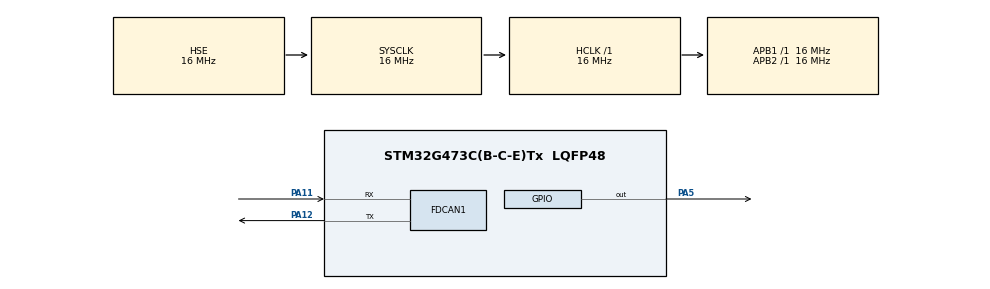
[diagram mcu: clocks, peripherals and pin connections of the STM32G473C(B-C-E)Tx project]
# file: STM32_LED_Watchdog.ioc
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FDCAN1.AutoRetransmission=ENABLE
FDCAN1.CalculateBaudRateNominal=1000000
FDCAN1.CalculateTimeBitNominal=1000
FDCAN1.CalculateTimeQuantumNominal=62.5
FDCAN1.NominalPrescaler=1
FDCAN1.NominalTimeSeg1=13
FDCAN1.NominalTimeSeg2=2
FDCAN1.StdFiltersNbr=1
IWDG.Prescaler=IWDG_PRESCALER_32
Mcu.Family=STM32G4
Mcu.Name=STM32G473C(B-C-E)Tx
Mcu.Package=LQFP48
NVIC.PriorityGroup=NVIC_PRIORITYGROUP_4
NVIC.TIM6_DAC_IRQn=true\:0\:0\:false\:false\:true\:true\:true\:true
PA11.Mode=FDCAN_Activate
PA11.Signal=FDCAN1_RX
PA12.Mode=FDCAN_Activate
PA12.Signal=FDCAN1_TX
PA5.Signal=GPIO_Output
PF0-OSC_IN.Mode=HSE-External-Clock-Source
PF0-OSC_IN.Signal=RCC_OSC_IN
ProjectManager.HeapSize=0x200
ProjectManager.StackSize=0x400
ProjectManager.TargetToolchain=STM32CubeIDE
RCC.AHBFreq_Value=16000000
RCC.APB1Freq_Value=16000000
RCC.APB1TimFreq_Value=16000000
RCC.APB2Freq_Value=16000000
RCC.APB2TimFreq_Value=16000000
RCC.CortexFreq_Value=16000000
RCC.EXTERNAL_CLOCK_VALUE=12288000
RCC.HCLKFreq_Value=16000000
RCC.HSE_VALUE=16000000
RCC.HSI48_VALUE=48000000
RCC.HSI_VALUE=16000000
RCC.LSE_VALUE=32768
RCC.PLLSourceVirtual=RCC_PLLSOURCE_HSE
RCC.SYSCLKFreq_VALUE=16000000
RCC.SYSCLKSource=RCC_SYSCLKSOURCE_HSE
RCC.USBFreq_Value=64000000
RCC.VCOOutputFreq_Value=128000000
TIM6.PeriodNoDither=99
TIM6.Prescaler=15999
VP_IWDG_VS_IWDG.Mode=IWDG_Activate
VP_SYS_VS_DBSignals.Mode=DisableDeadBatterySignals
VP_TIM6_VS_ClockSourceINT.Mode=Enable_Timer
board=custom

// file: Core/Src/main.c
/* USER CODE BEGIN Header */
/**
  ******************************************************************************
  * @file           : main.c
  * @brief          : Main program body
  ******************************************************************************
  * @attention
  *
  * Copyright (c) 2026 STMicroelectronics.
  * All rights reserved.
  *
  * This software is licensed under terms that can be found in the LICENSE file
  * in the root directory of this software component.
  * If no LICENSE file comes with this software, it is provided AS-IS.
  *
  ******************************************************************************
  */
/* USER CODE END Header */
#include "main.h"
#include "fdcan.h"
#include "iwdg.h"
#include "tim.h"
#include "gpio.h"

/* USER CODE BEGIN PV */
static uint32_t runTime = 0;	//czas dzialania programu w sekudnach
static uint32_t lastTick = 0;		//czas ostatniej wyslanej ramki
static uint8_t canData[2];	//2 bajty danych CAN
static FDCAN_TxHeaderTypeDef TxHeader;	//naglowek ramki

/* USER CODE END PV */

void SystemClock_Config(void);

int main(void)
{

  /* MCU Configuration--------------------------------------------------------*/

  /* Reset of all peripherals, Initializes the Flash interface and the Systick. */
  HAL_Init();

  /* Configure the system clock */
  SystemClock_Config();

  /* Initialize all configured peripherals */
  MX_GPIO_Init();
  MX_TIM6_Init();
  MX_IWDG_Init();
  MX_FDCAN1_Init();
  /* USER CODE BEGIN 2 */
  FDCAN_FilterTypeDef sFilterConfig = {0};

  sFilterConfig.IdType = FDCAN_STANDARD_ID;
  sFilterConfig.FilterIndex = 0;
  sFilterConfig.FilterType = FDCAN_FILTER_MASK;
  sFilterConfig.FilterConfig = FDCAN_FILTER_TO_RXFIFO0;
  sFilterConfig.FilterID1 = 0x000;
  sFilterConfig.FilterID2 = 0x000;

  if(HAL_FDCAN_ConfigFilter(&hfdcan1, &sFilterConfig) != HAL_OK){
	  Error_Handler();
  }

  TxHeader.Identifier = 0x738;
  TxHeader.IdType = FDCAN_STANDARD_ID;
  TxHeader.TxFrameType = FDCAN_DATA_FRAME;
  TxHeader.DataLength = FDCAN_DLC_BYTES_2;
  TxHeader.ErrorStateIndicator = FDCAN_ESI_ACTIVE;
  TxHeader.BitRateSwitch = FDCAN_BRS_OFF;
  TxHeader.FDFormat = FDCAN_CLASSIC_CAN;
  TxHeader.TxEventFifoControl = FDCAN_NO_TX_EVENTS;
  TxHeader.MessageMarker = 0;

  if(HAL_FDCAN_Start(&hfdcan1) != HAL_OK){		//uruchamia FDCAN1
	  Error_Handler();
  }
  HAL_TIM_Base_Start_IT(&htim6);		//uruchamia tim6 z obsługiwaniem przerwan
  /* USER CODE END 2 */

  /* Infinite loop */
  while (1)
  {

    /* USER CODE BEGIN 3 */
	  uint32_t currentTick = HAL_GetTick();

	  if((uint32_t)(currentTick - lastTick) >= 1000U){
		  lastTick = currentTick;
		  runTime ++;

		  canData[0] = (uint8_t)(runTime & 0xFFU);		//mlodsze 8bitow
		  canData[1] = (uint8_t)((runTime >> 8) & 0xFFU);		//starsze 8 bitow
		  if(HAL_FDCAN_AddMessageToTxFifoQ(&hfdcan1, &TxHeader, canData) != HAL_OK){	//wysylam ramke can do kolejki
			  Error_Handler();
		  }
	  }
	  HAL_IWDG_Refresh(&hiwdg); //odswiezanie watchdoga, gdy program dziala
  }
  /* USER CODE END 3 */
}

void SystemClock_Config(void)
{
  RCC_OscInitTypeDef RCC_OscInitStruct = {0};
  RCC_ClkInitTypeDef RCC_ClkInitStruct = {0};

  /** Configure the main internal regulator output voltage
  */
  HAL_PWREx_ControlVoltageScaling(PWR_REGULATOR_VOLTAGE_SCALE1);

  /** Initializes the RCC Oscillators according to the specified parameters
  * in the RCC_OscInitTypeDef structure.
  */
  RCC_OscInitStruct.OscillatorType = RCC_OSCILLATORTYPE_LSI|RCC_OSCILLATORTYPE_HSE;
  RCC_OscInitStruct.HSEState = RCC_HSE_BYPASS;
  RCC_OscInitStruct.LSIState = RCC_LSI_ON;
  RCC_OscInitStruct.PLL.PLLState = RCC_PLL_NONE;
  if (HAL_RCC_OscConfig(&RCC_OscInitStruct) != HAL_OK)
  {
    Error_Handler();
  }

  /** Initializes the CPU, AHB and APB buses clocks
  */
  RCC_ClkInitStruct.ClockType = RCC_CLOCKTYPE_HCLK|RCC_CLOCKTYPE_SYSCLK
                              |RCC_CLOCKTYPE_PCLK1|RCC_CLOCKTYPE_PCLK2;
  RCC_ClkInitStruct.SYSCLKSource = RCC_SYSCLKSOURCE_HSE;
  RCC_ClkInitStruct.AHBCLKDivider = RCC_SYSCLK_DIV1;
  RCC_ClkInitStruct.APB1CLKDivider = RCC_HCLK_DIV1;
  RCC_ClkInitStruct.APB2CLKDivider = RCC_HCLK_DIV1;

  if (HAL_RCC_ClockConfig(&RCC_ClkInitStruct, FLASH_LATENCY_0) != HAL_OK)
  {
    Error_Handler();
  }
}

/* USER CODE BEGIN 4 */
	void HAL_TIM_PeriodElapsedCallback(TIM_HandleTypeDef *timer){	//dzieki nazwie funkcja wykonuje sie sama, bez wywolywania w kodzie
		if(timer->Instance == TIM6){		//czy zdarzenie jest od tim6
			HAL_GPIO_TogglePin(GPIOA, GPIO_PIN_5);		//przelaczenie diody
		}
	}
/* USER CODE END 4 */

void Error_Handler(void)
{
  __disable_irq();
  while (1)
  {
  }
}
